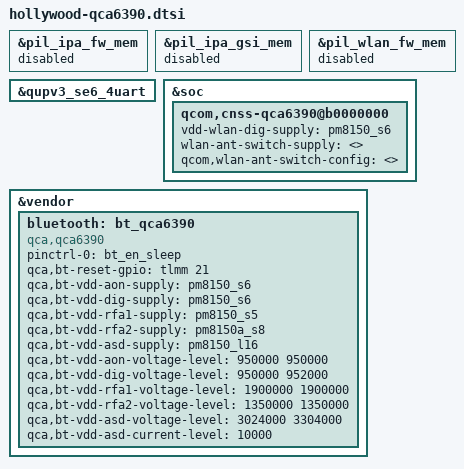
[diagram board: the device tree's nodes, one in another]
&pil_ipa_fw_mem {
	status = "disabled";
};

&pil_ipa_gsi_mem {
	status = "disabled";
};

&pil_wlan_fw_mem {
	status = "disabled";
};

&qupv3_se6_4uart {
	status = "ok";
};

&soc {
	qcom,cnss-qca6390@b0000000 {
		vdd-wlan-dig-supply = <&pm8150_s6>;
		wlan-ant-switch-supply = <>;
		qcom,wlan-ant-switch-config = <>;
	};
};

&vendor {
	bluetooth: bt_qca6390 {
		compatible = "qca,qca6390";
		pinctrl-names = "default";
		pinctrl-0 = <&bt_en_sleep>;
		qca,bt-reset-gpio = <&tlmm 21 0>; /* BT_EN */
		qca,bt-vdd-aon-supply = <&pm8150_s6>;
		qca,bt-vdd-dig-supply = <&pm8150_s6>;
		qca,bt-vdd-rfa1-supply = <&pm8150_s5>;
		qca,bt-vdd-rfa2-supply = <&pm8150a_s8>;
		qca,bt-vdd-asd-supply = <&pm8150_l16>;

		qca,bt-vdd-aon-voltage-level = <950000 950000>;
		qca,bt-vdd-dig-voltage-level = <950000 952000>;
		qca,bt-vdd-rfa1-voltage-level = <1900000 1900000>;
		qca,bt-vdd-rfa2-voltage-level = <1350000 1350000>;
		qca,bt-vdd-asd-voltage-level = <3024000 3304000>;

		qca,bt-vdd-asd-current-level = <10000>;
	};
};
